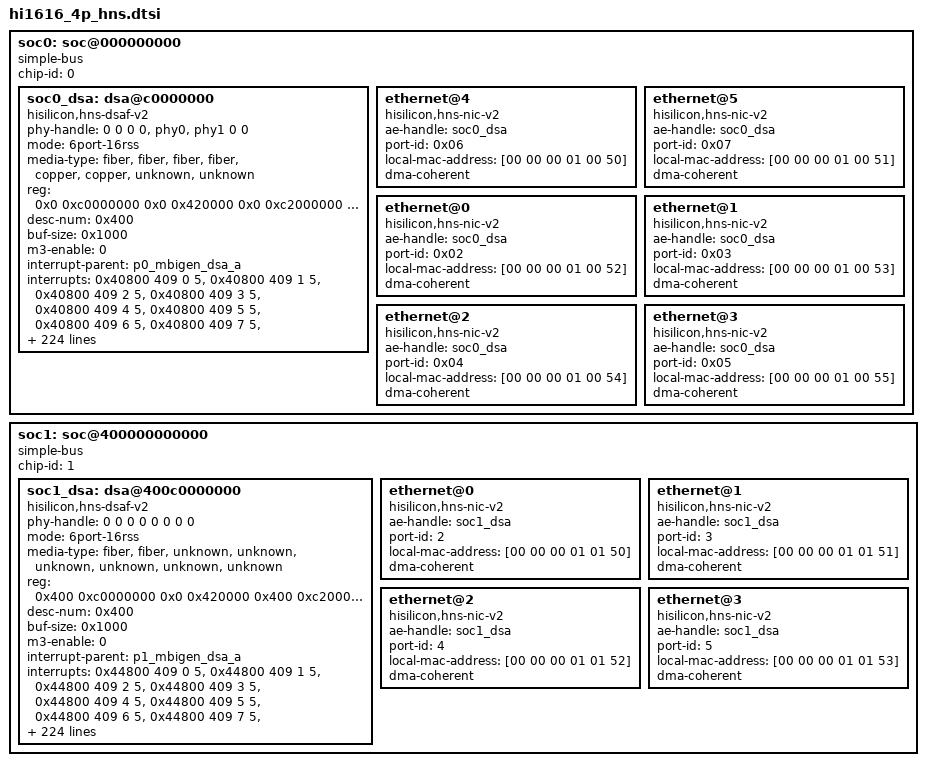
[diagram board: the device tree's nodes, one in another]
soc0: soc@000000000 {
	#address-cells = <2>;
	#size-cells = <2>;
	device_type = "soc";
	compatible = "simple-bus";
	ranges;
	chip-id = <0>;

	soc0_dsa: dsa@c0000000 {
		compatible = "hisilicon,hns-dsaf-v2";
		phy-handle = <0 0 0 0 &phy0 &phy1 0 0>;
		mode = "6port-16rss";
		media-type = "fiber", "fiber", "fiber", "fiber",
			"copper", "copper", "unknown", "unknown";

		reg = <0x0 0xc0000000 0x0 0x420000
				0x0 0xc2000000 0x0 0x300000
				0x0 0xc5000000 0x0 0x900000
				0x0 0xc7000000 0x0 0x60000>;

		desc-num = <0x400>;
		buf-size = <0x1000>;
		m3-enable = <0>;
		interrupt-parent  = <&p0_mbigen_dsa_a>;
		interrupts = <0x40800 409 0 5>,
					<0x40800 409 1 5>,
					<0x40800 409 2 5>,
					<0x40800 409 3 5>,
					<0x40800 409 4 5>,
					<0x40800 409 5 5>,
					<0x40800 409 6 5>,
					<0x40800 409 7 5>,
					<0x40800 409 8 5>,
					<0x40800 409 9 5>,
					<0x40800 409 10 5>,
					<0x40800 409 11 5>,
					<0x40800 409 12 5>,
					<0x40800 409 0 7>,
					<0x40800 409 1 7>,
					<0x40800 409 2 7>,
					<0x40800 409 3 7>,
					<0x40800 409 4 7>,
					<0x40800 409 5 7>,
					<0x40800 409 6 7>,
					<0x40800 409 7 7>,
					<0x40800 409 8 7>,
					<0x40800 409 9 7>,
					<0x40800 409 10 7>,
					<0x40800 409 11 7>,
					<0x40800 409 0 8>,
					<0x40800 409 1 8>,
					<0x40800 409 2 8>,
					<0x40800 409 3 8>,
					<0x40800 409 4 8>,
					<0x40800 409 5 8>,
					<0x40800 409 6 8>,
					<0x40800 409 7 8>,
					<0x40800 409 8 8>,
					<0x40800 409 9 8>,
					<0x40800 409 10 8>,
					<0x40800 409 11 8>,
					<0x40800 409 12 8>,
					<0x40800 409 13 8>,
					<0x40800 409 14 8>,
					<0x40800 409 15 8>,
					<0x40800 409 16 8>,
					<0x40800 409 17 8>,
					<0x40800 409 18 8>,
					<0x40800 409 19 8>,
					<0x40800 409 20 8>,
					<0x40800 409 21 8>,
					<0x40800 409 22 8>,
					<0x40800 409 23 8>,
					<0x40800 409 24 8>,
					<0x40800 409 25 8>,
					<0x40800 409 26 8>,
					<0x40800 409 27 8>,
					<0x40800 409 28 8>,
					<0x40800 409 29 8>,
					<0x40800 409 30 8>,
					<0x40800 409 31 8>,
					<0x40800 409 32 8>,
					<0x40800 409 33 8>,
					<0x40800 409 34 8>,
					<0x40800 409 35 8>,
					<0x40800 409 36 8>,
					<0x40800 409 37 8>,
					<0x40800 409 38 8>,
					<0x40800 409 39 8>,
					<0x40800 409 40 8>,
					<0x40800 409 41 8>,
					<0x40800 409 42 8>,
					<0x40800 409 43 8>,
					<0x40800 409 44 8>,
					<0x40800 409 45 8>,
					<0x40800 409 46 8>,
					<0x40800 409 47 8>,
					<0x40800 409 48 8>,
					<0x40800 409 49 8>,
					<0x40800 409 50 8>,
					<0x40800 409 51 8>,
					<0x40800 409 52 8>,
					<0x40800 409 53 8>,
					<0x40800 409 54 8>,
					<0x40800 409 55 8>,
					<0x40800 409 56 8>,
					<0x40800 409 57 8>,
					<0x40800 409 58 8>,
					<0x40800 409 59 8>,
					<0x40800 409 60 8>,
					<0x40800 409 61 8>,
					<0x40800 409 62 8>,
					<0x40800 409 63 8>,
					<0x40800 409 64 8>,
					<0x40800 409 65 8>,
					<0x40800 409 66 8>,
					<0x40800 409 67 8>,
					<0x40800 409 68 8>,
					<0x40800 409 69 8>,
					<0x40800 409 70 8>,
					<0x40800 409 71 8>,
					<0x40800 409 72 8>,
					<0x40800 409 73 8>,
					<0x40800 409 74 8>,
					<0x40800 409 75 8>,
					<0x40800 409 76 8>,
					<0x40800 409 77 8>,
					<0x40800 409 78 8>,
					<0x40800 409 79 8>,
					<0x40800 409 80 8>,
					<0x40800 409 81 8>,
					<0x40800 409 82 8>,
					<0x40800 409 83 8>,
					<0x40800 409 84 8>,
					<0x40800 409 85 8>,
					<0x40800 409 86 8>,
					<0x40800 409 87 8>,
					<0x40800 409 88 8>,
					<0x40800 409 89 8>,
					<0x40800 409 90 8>,
					<0x40800 409 91 8>,
					<0x40800 409 92 8>,
					<0x40800 409 93 8>,
					<0x40800 409 94 8>,
					<0x40800 409 95 8>,
					<0x40800 409 96 8>,
					<0x40800 409 97 8>,
					<0x40800 409 98 8>,
					<0x40800 409 99 8>,
					<0x40800 409 100 8>,
					<0x40800 409 101 8>,
					<0x40800 409 102 8>,
					<0x40800 409 103 8>,
					<0x40800 409 104 8>,
					<0x40800 409 105 8>,
					<0x40800 409 106 8>,
					<0x40800 409 107 8>,
					<0x40800 409 108 8>,
					<0x40800 409 109 8>,
					<0x40800 409 110 8>,
					<0x40800 409 111 8>,
					<0x40800 409 112 8>,
					<0x40800 409 113 8>,
					<0x40800 409 114 8>,
					<0x40800 409 115 8>,
					<0x40800 409 116 8>,
					<0x40800 409 117 8>,
					<0x40800 409 118 8>,
					<0x40800 409 119 8>,
					<0x40800 409 120 8>,
					<0x40800 409 121 8>,
					<0x40800 409 122 8>,
					<0x40800 409 123 8>,
					<0x40800 409 124 8>,
					<0x40800 409 125 8>,
					<0x40800 409 126 8>,
					<0x40800 409 127 8>,
					<0x40800 409 0 9>,
					<0x40800 409 1 9>,
					<0x40800 409 2 9>,
					<0x40800 409 3 9>,
					<0x40800 409 4 9>,
					<0x40800 409 5 9>,
					<0x40800 409 6 9>,
					<0x40800 409 7 9>,
					<0x40800 409 8 9>,
					<0x40800 409 9 9>,
					<0x40800 409 10 9>,
					<0x40800 409 11 9>,
					<0x40800 409 12 9>,
					<0x40800 409 13 9>,
					<0x40800 409 14 9>,
					<0x40800 409 15 9>,
					<0x40800 409 16 9>,
					<0x40800 409 17 9>,
					<0x40800 409 18 9>,
					<0x40800 409 19 9>,
					<0x40800 409 20 9>,
					<0x40800 409 21 9>,
					<0x40800 409 22 9>,
					<0x40800 409 23 9>,
					<0x40800 409 24 9>,
					<0x40800 409 25 9>,
					<0x40800 409 26 9>,
					<0x40800 409 27 9>,
					<0x40800 409 28 9>,
					<0x40800 409 29 9>,
					<0x40800 409 30 9>,
					<0x40800 409 31 9>,
					<0x40800 409 32 9>,
					<0x40800 409 33 9>,
					<0x40800 409 34 9>,
					<0x40800 409 35 9>,
					<0x40800 409 36 9>,
					<0x40800 409 37 9>,
					<0x40800 409 38 9>,
					<0x40800 409 39 9>,
					<0x40800 409 40 9>,
					<0x40800 409 41 9>,
					<0x40800 409 42 9>,
					<0x40800 409 43 9>,
					<0x40800 409 44 9>,
					<0x40800 409 45 9>,
					<0x40800 409 46 9>,
					<0x40800 409 47 9>,
					<0x40800 409 48 9>,
					<0x40800 409 49 9>,
					<0x40800 409 50 9>,
					<0x40800 409 51 9>,
					<0x40800 409 52 9>,
					<0x40800 409 53 9>,
					<0x40800 409 54 9>,
					<0x40800 409 55 9>,
					<0x40800 409 56 9>,
					<0x40800 409 57 9>,
					<0x40800 409 58 9>,
					<0x40800 409 59 9>,
					<0x40800 409 60 9>,
					<0x40800 409 61 9>,
					<0x40800 409 62 9>,
					<0x40800 409 63 9>,
					<0x40800 409 64 9>,
					<0x40800 409 65 9>,
					<0x40800 409 66 9>,
					<0x40800 409 67 9>,
					<0x40800 409 68 9>,
					<0x40800 409 69 9>,
					<0x40800 409 70 9>,
					<0x40800 409 71 9>,
					<0x40800 409 72 9>,
					<0x40800 409 73 9>,
					<0x40800 409 74 9>,
					<0x40800 409 75 9>,
					<0x40800 409 76 9>,
					<0x40800 409 77 9>,
					<0x40800 409 78 9>,
					<0x40800 409 79 9>,
					<0x40800 409 80 9>,
					<0x40800 409 81 9>,
					<0x40800 409 82 9>,
					<0x40800 409 83 9>,
					<0x40800 409 84 9>,
					<0x40800 409 85 9>,
					<0x40800 409 86 9>,
					<0x40800 409 87 9>,
					<0x40800 409 88 9>,
					<0x40800 409 89 9>,
					<0x40800 409 90 9>,
					<0x40800 409 91 9>,
					<0x40800 409 92 9>,
					<0x40800 409 93 9>,
					<0x40800 409 94 9>,
					<0x40800 409 95 9>,
					<0x40800 409 96 9>,
					<0x40800 409 97 9>,
					<0x40800 409 98 9>,
					<0x40800 409 99 9>,
					<0x40800 409 100 9>,
					<0x40800 409 101 9>,
					<0x40800 409 102 9>,
					<0x40800 409 103 9>,
					<0x40800 409 104 9>,
					<0x40800 409 105 9>,
					<0x40800 409 106 9>,
					<0x40800 409 107 9>,
					<0x40800 409 108 9>,
					<0x40800 409 109 9>,
					<0x40800 409 110 9>,
					<0x40800 409 111 9>,
					<0x40800 409 112 9>,
					<0x40800 409 113 9>,
					<0x40800 409 114 9>,
					<0x40800 409 115 9>,
					<0x40800 409 116 9>,
					<0x40800 409 117 9>,
					<0x40800 409 118 9>,
					<0x40800 409 119 9>,
					<0x40800 409 120 9>,
					<0x40800 409 121 9>,
					<0x40800 409 122 9>,
					<0x40800 409 123 9>,
					<0x40800 409 124 9>,
					<0x40800 409 125 9>,
					<0x40800 409 126 9>,
					<0x40800 409 127 9>,
					<0x40800 409 0 10>,
					<0x40800 409 1 10>,
					<0x40800 409 2 10>,
					<0x40800 409 3 10>,
					<0x40800 409 4 10>,
					<0x40800 409 5 10>,
					<0x40800 409 6 10>,
					<0x40800 409 7 10>,
					<0x40800 409 8 10>,
					<0x40800 409 9 10>,
					<0x40800 409 10 10>,
					<0x40800 409 11 10>,
					<0x40800 409 12 10>,
					<0x40800 409 13 10>,
					<0x40800 409 14 10>,
					<0x40800 409 15 10>,
					<0x40800 409 16 10>,
					<0x40800 409 17 10>,
					<0x40800 409 18 10>,
					<0x40800 409 19 10>,
					<0x40800 409 20 10>,
					<0x40800 409 21 10>,
					<0x40800 409 22 10>,
					<0x40800 409 23 10>,
					<0x40800 409 24 10>,
					<0x40800 409 25 10>,
					<0x40800 409 26 10>,
					<0x40800 409 27 10>,
					<0x40800 409 28 10>,
					<0x40800 409 29 10>,
					<0x40800 409 30 10>,
					<0x40800 409 31 10>,
					<0x40800 409 32 10>,
					<0x40800 409 33 10>,
					<0x40800 409 34 10>,
					<0x40800 409 35 10>,
					<0x40800 409 36 10>,
					<0x40800 409 37 10>,
					<0x40800 409 38 10>,
					<0x40800 409 39 10>,
					<0x40800 409 40 10>,
					<0x40800 409 41 10>,
					<0x40800 409 42 10>,
					<0x40800 409 43 10>,
					<0x40800 409 44 10>,
					<0x40800 409 45 10>,
					<0x40800 409 46 10>,
					<0x40800 409 47 10>,
					<0x40800 409 48 10>,
					<0x40800 409 49 10>,
					<0x40800 409 50 10>,
					<0x40800 409 51 10>,
					<0x40800 409 52 10>,
					<0x40800 409 53 10>,
					<0x40800 409 54 10>,
					<0x40800 409 55 10>,
					<0x40800 409 56 10>,
					<0x40800 409 57 10>,
					<0x40800 409 58 10>,
					<0x40800 409 59 10>,
					<0x40800 409 60 10>,
					<0x40800 409 61 10>,
					<0x40800 409 62 10>,
					<0x40800 409 63 10>,
					<0x40800 409 64 10>,
					<0x40800 409 65 10>,
					<0x40800 409 66 10>,
					<0x40800 409 67 10>,
					<0x40800 409 68 10>,
					<0x40800 409 69 10>,
					<0x40800 409 70 10>,
					<0x40800 409 71 10>,
					<0x40800 409 72 10>,
					<0x40800 409 73 10>,
					<0x40800 409 74 10>,
					<0x40800 409 75 10>,
					<0x40800 409 76 10>,
					<0x40800 409 77 10>,
					<0x40800 409 78 10>,
					<0x40800 409 79 10>,
					<0x40800 409 80 10>,
					<0x40800 409 81 10>,
					<0x40800 409 82 10>,
					<0x40800 409 83 10>,
					<0x40800 409 84 10>,
					<0x40800 409 85 10>,
					<0x40800 409 86 10>,
					<0x40800 409 87 10>,
					<0x40800 409 88 10>,
					<0x40800 409 89 10>,
					<0x40800 409 90 10>,
					<0x40800 409 91 10>,
					<0x40800 409 92 10>,
					<0x40800 409 93 10>,
					<0x40800 409 94 10>,
					<0x40800 409 95 10>,
					<0x40800 409 96 10>,
					<0x40800 409 97 10>,
					<0x40800 409 98 10>,
					<0x40800 409 99 10>,
					<0x40800 409 100 10>,
					<0x40800 409 101 10>,
					<0x40800 409 102 10>,
					<0x40800 409 103 10>,
					<0x40800 409 104 10>,
					<0x40800 409 105 10>,
					<0x40800 409 106 10>,
					<0x40800 409 107 10>,
					<0x40800 409 108 10>,
					<0x40800 409 109 10>,
					<0x40800 409 110 10>,
					<0x40800 409 111 10>,
					<0x40800 409 112 10>,
					<0x40800 409 113 10>,
					<0x40800 409 114 10>,
					<0x40800 409 115 10>,
					<0x40800 409 116 10>,
					<0x40800 409 117 10>,
					<0x40800 409 118 10>,
					<0x40800 409 119 10>,
					<0x40800 409 120 10>,
					<0x40800 409 121 10>,
					<0x40800 409 122 10>,
					<0x40800 409 123 10>,
					<0x40800 409 124 10>,
					<0x40800 409 125 10>,
					<0x40800 409 126 10>,
					<0x40800 409 127 10>,
					<0x40b1c 9 0 6>,
					<0x40b1c 9 1 6>,
					<0x40b1c 9 2 6>,
					<0x40b1c 9 3 6>,
					<0x40b1c 9 4 6>,
					<0x40b1c 9 5 6>,
					<0x40b1c 9 6 6>,
					<0x40b1c 9 7 6>,
					<0x40b1c 9 8 6>,
					<0x40b1d 9 9 6>,
					<0x40b1d 9 10 6>,
					<0x40b1d 9 11 6>,
					<0x40b1d 9 12 6>,
					<0x40b1d 9 13 6>,
					<0x40b1d 9 14 6>,
					<0x40b1d 9 15 6>,
					<0x40b1d 9 16 6>,
					<0x40b1d 9 17 6>,
					<0x40b1f 18 51 6>,
					<0x40b1f 18 52 6>,
					<0x40b1f 18 53 6>,
					<0x40b1f 18 54 6>,
					<0x40b1f 18 55 6>,
					<0x40b1f 18 56 6>,
					<0x40b1f 18 57 6>,
					<0x40b1f 18 58 6>,
					<0x40b1f 18 59 6>,
					<0x40b1f 18 60 6>,
					<0x40b1f 18 61 6>,
					<0x40b1f 18 62 6>,
					<0x40b1f 18 63 6>,
					<0x40b1f 18 64 6>,
					<0x40b1f 18 65 6>,
					<0x40b1f 18 66 6>,
					<0x40b1f 18 67 6>,
					<0x40b1f 18 68 6>,
					<0x40881 12 13 5>,
					<0x40881 12 14 5>,
					<0x40881 12 15 5>,
					<0x40881 12 16 5>,
					<0x40881 12 17 5>,
					<0x40881 12 18 5>,
					<0x40881 12 19 5>,
					<0x40881 12 20 5>,
					<0x40881 12 21 5>,
					<0x40881 12 22 5>,
					<0x40881 12 23 5>,
					<0x40881 12 24 5>;
		dma-coherent;
	};

	ethernet@4 { /* eth0 */
			compatible = "hisilicon,hns-nic-v2";
			ae-handle = <&soc0_dsa>;
			port-id = <0x06>;
			local-mac-address = [00 00 00 01 00 50];
			dma-coherent;
	};

	ethernet@5 { /* eth1 */
			compatible = "hisilicon,hns-nic-v2";
			ae-handle = <&soc0_dsa>;
			port-id = <0x07>;
			local-mac-address = [00 00 00 01 00 51];
			dma-coherent;
	};

	ethernet@0 { /* eth2 */
			compatible = "hisilicon,hns-nic-v2";
			ae-handle = <&soc0_dsa>;
			port-id = <0x02>;
			local-mac-address = [00 00 00 01 00 52];
			dma-coherent;
	};

	ethernet@1 { /* eth3 */
			compatible = "hisilicon,hns-nic-v2";
			ae-handle = <&soc0_dsa>;
			port-id = <0x03>;
			local-mac-address = [00 00 00 01 00 53];
			dma-coherent;
	};

	ethernet@2 { /* eth4 */
			compatible = "hisilicon,hns-nic-v2";
			ae-handle = <&soc0_dsa>;
			port-id = <0x04>;
			local-mac-address = [00 00 00 01 00 54];
			dma-coherent;
	};

	ethernet@3 { /* eth5 */
			compatible = "hisilicon,hns-nic-v2";
			ae-handle = <&soc0_dsa>;
			port-id = <0x05>;
			local-mac-address = [00 00 00 01 00 55];
			dma-coherent;
	};
}; /* soc0 */

soc1: soc@400000000000 {
	#address-cells = <2>;
	#size-cells = <2>;
	device_type = "soc";
	compatible = "simple-bus";
	ranges;
	chip-id = <1>;

	soc1_dsa: dsa@400c0000000 {
		compatible = "hisilicon,hns-dsaf-v2";
		phy-handle = <0 0 0 0 0 0 0 0>;
		mode = "6port-16rss";
		media-type = "fiber", "fiber", "unknown", "unknown",
			"unknown", "unknown", "unknown", "unknown";

		reg = <0x400 0xc0000000 0x0 0x420000
				0x400 0xc2000000 0x0 0x300000
				0x400 0xc5000000 0x0 0x900000
				0x400 0xc7000000 0x0 0x60000>;

		desc-num = <0x400>;
		buf-size = <0x1000>;
		m3-enable = <0>;
		interrupt-parent  = <&p1_mbigen_dsa_a>;
		interrupts = <0x44800 409 0 5>,
					<0x44800 409 1 5>,
					<0x44800 409 2 5>,
					<0x44800 409 3 5>,
					<0x44800 409 4 5>,
					<0x44800 409 5 5>,
					<0x44800 409 6 5>,
					<0x44800 409 7 5>,
					<0x44800 409 8 5>,
					<0x44800 409 9 5>,
					<0x44800 409 10 5>,
					<0x44800 409 11 5>,
					<0x44800 409 12 5>,
					<0x44800 409 0 7>,
					<0x44800 409 1 7>,
					<0x44800 409 2 7>,
					<0x44800 409 3 7>,
					<0x44800 409 4 7>,
					<0x44800 409 5 7>,
					<0x44800 409 6 7>,
					<0x44800 409 7 7>,
					<0x44800 409 8 7>,
					<0x44800 409 9 7>,
					<0x44800 409 10 7>,
					<0x44800 409 11 7>,
					<0x44800 409 0 8>,
					<0x44800 409 1 8>,
					<0x44800 409 2 8>,
					<0x44800 409 3 8>,
					<0x44800 409 4 8>,
					<0x44800 409 5 8>,
					<0x44800 409 6 8>,
					<0x44800 409 7 8>,
					<0x44800 409 8 8>,
					<0x44800 409 9 8>,
					<0x44800 409 10 8>,
					<0x44800 409 11 8>,
					<0x44800 409 12 8>,
					<0x44800 409 13 8>,
					<0x44800 409 14 8>,
					<0x44800 409 15 8>,
					<0x44800 409 16 8>,
					<0x44800 409 17 8>,
					<0x44800 409 18 8>,
					<0x44800 409 19 8>,
					<0x44800 409 20 8>,
					<0x44800 409 21 8>,
					<0x44800 409 22 8>,
					<0x44800 409 23 8>,
					<0x44800 409 24 8>,
					<0x44800 409 25 8>,
					<0x44800 409 26 8>,
					<0x44800 409 27 8>,
					<0x44800 409 28 8>,
					<0x44800 409 29 8>,
					<0x44800 409 30 8>,
					<0x44800 409 31 8>,
					<0x44800 409 32 8>,
					<0x44800 409 33 8>,
					<0x44800 409 34 8>,
					<0x44800 409 35 8>,
					<0x44800 409 36 8>,
					<0x44800 409 37 8>,
					<0x44800 409 38 8>,
					<0x44800 409 39 8>,
					<0x44800 409 40 8>,
					<0x44800 409 41 8>,
					<0x44800 409 42 8>,
					<0x44800 409 43 8>,
					<0x44800 409 44 8>,
					<0x44800 409 45 8>,
					<0x44800 409 46 8>,
					<0x44800 409 47 8>,
					<0x44800 409 48 8>,
					<0x44800 409 49 8>,
					<0x44800 409 50 8>,
					<0x44800 409 51 8>,
					<0x44800 409 52 8>,
					<0x44800 409 53 8>,
					<0x44800 409 54 8>,
					<0x44800 409 55 8>,
					<0x44800 409 56 8>,
					<0x44800 409 57 8>,
					<0x44800 409 58 8>,
					<0x44800 409 59 8>,
					<0x44800 409 60 8>,
					<0x44800 409 61 8>,
					<0x44800 409 62 8>,
					<0x44800 409 63 8>,
					<0x44800 409 64 8>,
					<0x44800 409 65 8>,
					<0x44800 409 66 8>,
					<0x44800 409 67 8>,
					<0x44800 409 68 8>,
					<0x44800 409 69 8>,
					<0x44800 409 70 8>,
					<0x44800 409 71 8>,
					<0x44800 409 72 8>,
					<0x44800 409 73 8>,
					<0x44800 409 74 8>,
					<0x44800 409 75 8>,
					<0x44800 409 76 8>,
					<0x44800 409 77 8>,
					<0x44800 409 78 8>,
					<0x44800 409 79 8>,
					<0x44800 409 80 8>,
					<0x44800 409 81 8>,
					<0x44800 409 82 8>,
					<0x44800 409 83 8>,
					<0x44800 409 84 8>,
					<0x44800 409 85 8>,
					<0x44800 409 86 8>,
					<0x44800 409 87 8>,
					<0x44800 409 88 8>,
					<0x44800 409 89 8>,
					<0x44800 409 90 8>,
					<0x44800 409 91 8>,
					<0x44800 409 92 8>,
					<0x44800 409 93 8>,
					<0x44800 409 94 8>,
					<0x44800 409 95 8>,
					<0x44800 409 96 8>,
					<0x44800 409 97 8>,
					<0x44800 409 98 8>,
					<0x44800 409 99 8>,
					<0x44800 409 100 8>,
					<0x44800 409 101 8>,
					<0x44800 409 102 8>,
					<0x44800 409 103 8>,
					<0x44800 409 104 8>,
					<0x44800 409 105 8>,
					<0x44800 409 106 8>,
					<0x44800 409 107 8>,
					<0x44800 409 108 8>,
					<0x44800 409 109 8>,
					<0x44800 409 110 8>,
					<0x44800 409 111 8>,
					<0x44800 409 112 8>,
					<0x44800 409 113 8>,
					<0x44800 409 114 8>,
					<0x44800 409 115 8>,
					<0x44800 409 116 8>,
					<0x44800 409 117 8>,
					<0x44800 409 118 8>,
					<0x44800 409 119 8>,
					<0x44800 409 120 8>,
					<0x44800 409 121 8>,
					<0x44800 409 122 8>,
					<0x44800 409 123 8>,
					<0x44800 409 124 8>,
					<0x44800 409 125 8>,
					<0x44800 409 126 8>,
					<0x44800 409 127 8>,
					<0x44800 409 0 9>,
					<0x44800 409 1 9>,
					<0x44800 409 2 9>,
					<0x44800 409 3 9>,
					<0x44800 409 4 9>,
					<0x44800 409 5 9>,
					<0x44800 409 6 9>,
					<0x44800 409 7 9>,
					<0x44800 409 8 9>,
					<0x44800 409 9 9>,
					<0x44800 409 10 9>,
					<0x44800 409 11 9>,
					<0x44800 409 12 9>,
					<0x44800 409 13 9>,
					<0x44800 409 14 9>,
					<0x44800 409 15 9>,
					<0x44800 409 16 9>,
					<0x44800 409 17 9>,
					<0x44800 409 18 9>,
					<0x44800 409 19 9>,
					<0x44800 409 20 9>,
					<0x44800 409 21 9>,
					<0x44800 409 22 9>,
					<0x44800 409 23 9>,
					<0x44800 409 24 9>,
					<0x44800 409 25 9>,
					<0x44800 409 26 9>,
					<0x44800 409 27 9>,
					<0x44800 409 28 9>,
					<0x44800 409 29 9>,
					<0x44800 409 30 9>,
					<0x44800 409 31 9>,
					<0x44800 409 32 9>,
					<0x44800 409 33 9>,
					<0x44800 409 34 9>,
					<0x44800 409 35 9>,
					<0x44800 409 36 9>,
					<0x44800 409 37 9>,
					<0x44800 409 38 9>,
					<0x44800 409 39 9>,
					<0x44800 409 40 9>,
					<0x44800 409 41 9>,
					<0x44800 409 42 9>,
					<0x44800 409 43 9>,
					<0x44800 409 44 9>,
					<0x44800 409 45 9>,
					<0x44800 409 46 9>,
					<0x44800 409 47 9>,
					<0x44800 409 48 9>,
					<0x44800 409 49 9>,
					<0x44800 409 50 9>,
					<0x44800 409 51 9>,
					<0x44800 409 52 9>,
					<0x44800 409 53 9>,
					<0x44800 409 54 9>,
					<0x44800 409 55 9>,
					<0x44800 409 56 9>,
					<0x44800 409 57 9>,
					<0x44800 409 58 9>,
					<0x44800 409 59 9>,
					<0x44800 409 60 9>,
					<0x44800 409 61 9>,
					<0x44800 409 62 9>,
					<0x44800 409 63 9>,
					<0x44800 409 64 9>,
					<0x44800 409 65 9>,
					<0x44800 409 66 9>,
					<0x44800 409 67 9>,
					<0x44800 409 68 9>,
					<0x44800 409 69 9>,
					<0x44800 409 70 9>,
					<0x44800 409 71 9>,
					<0x44800 409 72 9>,
					<0x44800 409 73 9>,
					<0x44800 409 74 9>,
					<0x44800 409 75 9>,
					<0x44800 409 76 9>,
					<0x44800 409 77 9>,
					<0x44800 409 78 9>,
					<0x44800 409 79 9>,
					<0x44800 409 80 9>,
					<0x44800 409 81 9>,
					<0x44800 409 82 9>,
					<0x44800 409 83 9>,
					<0x44800 409 84 9>,
					<0x44800 409 85 9>,
					<0x44800 409 86 9>,
					<0x44800 409 87 9>,
					<0x44800 409 88 9>,
					<0x44800 409 89 9>,
					<0x44800 409 90 9>,
					<0x44800 409 91 9>,
					<0x44800 409 92 9>,
					<0x44800 409 93 9>,
					<0x44800 409 94 9>,
					<0x44800 409 95 9>,
					<0x44800 409 96 9>,
					<0x44800 409 97 9>,
					<0x44800 409 98 9>,
					<0x44800 409 99 9>,
					<0x44800 409 100 9>,
					<0x44800 409 101 9>,
					<0x44800 409 102 9>,
					<0x44800 409 103 9>,
					<0x44800 409 104 9>,
					<0x44800 409 105 9>,
					<0x44800 409 106 9>,
					<0x44800 409 107 9>,
					<0x44800 409 108 9>,
					<0x44800 409 109 9>,
					<0x44800 409 110 9>,
					<0x44800 409 111 9>,
					<0x44800 409 112 9>,
					<0x44800 409 113 9>,
					<0x44800 409 114 9>,
					<0x44800 409 115 9>,
					<0x44800 409 116 9>,
					<0x44800 409 117 9>,
					<0x44800 409 118 9>,
					<0x44800 409 119 9>,
					<0x44800 409 120 9>,
					<0x44800 409 121 9>,
					<0x44800 409 122 9>,
					<0x44800 409 123 9>,
					<0x44800 409 124 9>,
					<0x44800 409 125 9>,
					<0x44800 409 126 9>,
					<0x44800 409 127 9>,
					<0x44800 409 0 10>,
					<0x44800 409 1 10>,
					<0x44800 409 2 10>,
					<0x44800 409 3 10>,
					<0x44800 409 4 10>,
					<0x44800 409 5 10>,
					<0x44800 409 6 10>,
					<0x44800 409 7 10>,
					<0x44800 409 8 10>,
					<0x44800 409 9 10>,
					<0x44800 409 10 10>,
					<0x44800 409 11 10>,
					<0x44800 409 12 10>,
					<0x44800 409 13 10>,
					<0x44800 409 14 10>,
					<0x44800 409 15 10>,
					<0x44800 409 16 10>,
					<0x44800 409 17 10>,
					<0x44800 409 18 10>,
					<0x44800 409 19 10>,
					<0x44800 409 20 10>,
					<0x44800 409 21 10>,
					<0x44800 409 22 10>,
					<0x44800 409 23 10>,
					<0x44800 409 24 10>,
					<0x44800 409 25 10>,
					<0x44800 409 26 10>,
					<0x44800 409 27 10>,
					<0x44800 409 28 10>,
					<0x44800 409 29 10>,
					<0x44800 409 30 10>,
					<0x44800 409 31 10>,
					<0x44800 409 32 10>,
					<0x44800 409 33 10>,
					<0x44800 409 34 10>,
					<0x44800 409 35 10>,
					<0x44800 409 36 10>,
					<0x44800 409 37 10>,
					<0x44800 409 38 10>,
					<0x44800 409 39 10>,
					<0x44800 409 40 10>,
					<0x44800 409 41 10>,
					<0x44800 409 42 10>,
					<0x44800 409 43 10>,
					<0x44800 409 44 10>,
					<0x44800 409 45 10>,
					<0x44800 409 46 10>,
					<0x44800 409 47 10>,
					<0x44800 409 48 10>,
					<0x44800 409 49 10>,
					<0x44800 409 50 10>,
					<0x44800 409 51 10>,
					<0x44800 409 52 10>,
					<0x44800 409 53 10>,
					<0x44800 409 54 10>,
					<0x44800 409 55 10>,
					<0x44800 409 56 10>,
					<0x44800 409 57 10>,
					<0x44800 409 58 10>,
					<0x44800 409 59 10>,
					<0x44800 409 60 10>,
					<0x44800 409 61 10>,
					<0x44800 409 62 10>,
					<0x44800 409 63 10>,
					<0x44800 409 64 10>,
					<0x44800 409 65 10>,
					<0x44800 409 66 10>,
					<0x44800 409 67 10>,
					<0x44800 409 68 10>,
					<0x44800 409 69 10>,
					<0x44800 409 70 10>,
					<0x44800 409 71 10>,
					<0x44800 409 72 10>,
					<0x44800 409 73 10>,
					<0x44800 409 74 10>,
					<0x44800 409 75 10>,
					<0x44800 409 76 10>,
					<0x44800 409 77 10>,
					<0x44800 409 78 10>,
					<0x44800 409 79 10>,
					<0x44800 409 80 10>,
					<0x44800 409 81 10>,
					<0x44800 409 82 10>,
					<0x44800 409 83 10>,
					<0x44800 409 84 10>,
					<0x44800 409 85 10>,
					<0x44800 409 86 10>,
					<0x44800 409 87 10>,
					<0x44800 409 88 10>,
					<0x44800 409 89 10>,
					<0x44800 409 90 10>,
					<0x44800 409 91 10>,
					<0x44800 409 92 10>,
					<0x44800 409 93 10>,
					<0x44800 409 94 10>,
					<0x44800 409 95 10>,
					<0x44800 409 96 10>,
					<0x44800 409 97 10>,
					<0x44800 409 98 10>,
					<0x44800 409 99 10>,
					<0x44800 409 100 10>,
					<0x44800 409 101 10>,
					<0x44800 409 102 10>,
					<0x44800 409 103 10>,
					<0x44800 409 104 10>,
					<0x44800 409 105 10>,
					<0x44800 409 106 10>,
					<0x44800 409 107 10>,
					<0x44800 409 108 10>,
					<0x44800 409 109 10>,
					<0x44800 409 110 10>,
					<0x44800 409 111 10>,
					<0x44800 409 112 10>,
					<0x44800 409 113 10>,
					<0x44800 409 114 10>,
					<0x44800 409 115 10>,
					<0x44800 409 116 10>,
					<0x44800 409 117 10>,
					<0x44800 409 118 10>,
					<0x44800 409 119 10>,
					<0x44800 409 120 10>,
					<0x44800 409 121 10>,
					<0x44800 409 122 10>,
					<0x44800 409 123 10>,
					<0x44800 409 124 10>,
					<0x44800 409 125 10>,
					<0x44800 409 126 10>,
					<0x44800 409 127 10>,
					<0x44b1c 9 0 6>,
					<0x44b1c 9 1 6>,
					<0x44b1c 9 2 6>,
					<0x44b1c 9 3 6>,
					<0x44b1c 9 4 6>,
					<0x44b1c 9 5 6>,
					<0x44b1c 9 6 6>,
					<0x44b1c 9 7 6>,
					<0x44b1c 9 8 6>,
					<0x44b1d 9 9 6>,
					<0x44b1d 9 10 6>,
					<0x44b1d 9 11 6>,
					<0x44b1d 9 12 6>,
					<0x44b1d 9 13 6>,
					<0x44b1d 9 14 6>,
					<0x44b1d 9 15 6>,
					<0x44b1d 9 16 6>,
					<0x44b1d 9 17 6>,
					<0x44b1f 18 51 6>,
					<0x44b1f 18 52 6>,
					<0x44b1f 18 53 6>,
					<0x44b1f 18 54 6>,
					<0x44b1f 18 55 6>,
					<0x44b1f 18 56 6>,
					<0x44b1f 18 57 6>,
					<0x44b1f 18 58 6>,
					<0x44b1f 18 59 6>,
					<0x44b1f 18 60 6>,
					<0x44b1f 18 61 6>,
					<0x44b1f 18 62 6>,
					<0x44b1f 18 63 6>,
					<0x44b1f 18 64 6>,
					<0x44b1f 18 65 6>,
					<0x44b1f 18 66 6>,
					<0x44b1f 18 67 6>,
					<0x44b1f 18 68 6>,
					<0x44881 12 13 5>,
					<0x44881 12 14 5>,
					<0x44881 12 15 5>,
					<0x44881 12 16 5>,
					<0x44881 12 17 5>,
					<0x44881 12 18 5>,
					<0x44881 12 19 5>,
					<0x44881 12 20 5>,
					<0x44881 12 21 5>,
					<0x44881 12 22 5>,
					<0x44881 12 23 5>,
					<0x44881 12 24 5>;
		dma-coherent;
	};

	ethernet@0 { /* eth6 */
			compatible = "hisilicon,hns-nic-v2";
			ae-handle = <&soc1_dsa>;
			port-id = <2>;
			local-mac-address = [00 00 00 01 01 50];
			dma-coherent;
	};

	ethernet@1 { /* eth7 */
			compatible = "hisilicon,hns-nic-v2";
			ae-handle = <&soc1_dsa>;
			port-id = <3>;
			local-mac-address = [00 00 00 01 01 51];
			dma-coherent;
	};

	ethernet@2 { /* eth8 */
			compatible = "hisilicon,hns-nic-v2";
			ae-handle = <&soc1_dsa>;
			port-id = <4>;
			local-mac-address = [00 00 00 01 01 52];
			dma-coherent;
	};

	ethernet@3 { /* eth9 */
			compatible = "hisilicon,hns-nic-v2";
			ae-handle = <&soc1_dsa>;
			port-id = <5>;
			local-mac-address = [00 00 00 01 01 53];
			dma-coherent;
	};
}; /* soc1 */
